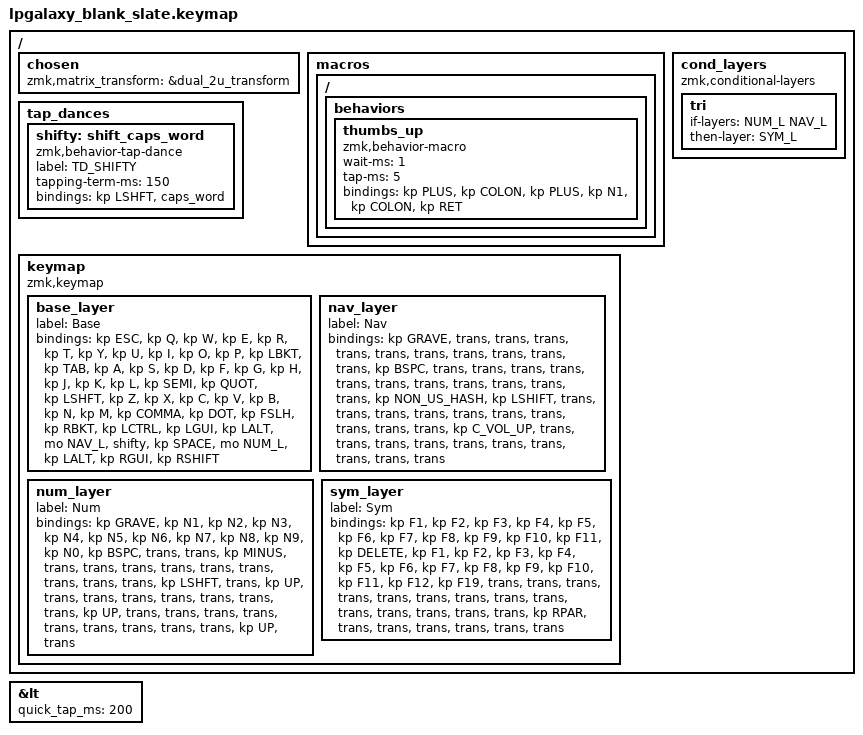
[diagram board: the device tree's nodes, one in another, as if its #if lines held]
/*
 * Copyright (c) 2022 Pete Johanson
 *
 * SPDX-License-Identifier: MIT
 */

#include <behaviors.dtsi>
#include <dt-bindings/zmk/keys.h>
#include <dt-bindings/zmk/bt.h>
#include <dt-bindings/zmk/outputs.h>

#define QWERTY_BASE 1

#define TBLE_MIT     1
// #define TBLE_MIT     1
// #define TBLE_DUAL_2U 1

#define NAV_L 1
#define NUM_L 2
#define SYM_L 3

// Using layer taps on thumbs, having quick tap as well helps w/ repeating space/backspace
&lt { quick_tap_ms = <200>; };

#define BT(n) BT_SEL n

/ {
    chosen {
       zmk,matrix_transform =
#ifdef TBLE_DUAL_2U
                       &dual_2u_transform;
#elif defined(TBLE_MIT)
                       &mit_transform;
#else
                       &ortho_transform;
#endif
    };

    macros {
      ZMK_MACRO(thumbs_up,
		wait-ms = <1>;
		tap-ms = <5>;
                bindings = <&kp PLUS &kp COLON &kp PLUS &kp N1 &kp COLON &kp RET>;
		)
    };
    
    tap_dances {
    	shifty: shift_caps_word {
		compatible = "zmk,behavior-tap-dance";
		label = "TD_SHIFTY";
		#binding-cells = <0>;
		tapping-term-ms = <150>;
		bindings = <&kp LSHFT>, <&caps_word>;
	};
    };

// Conditional layer only when we have less thumb keys
#ifdef TBLE_DUAL_2U
    cond_layers {
        compatible = "zmk,conditional-layers";
	tri {
	    if-layers = <NUM_L NAV_L>;
	    then-layer = <SYM_L>;
        };
    };
#endif

    keymap {
        compatible = "zmk,keymap";

        base_layer {
            label = "Base";
            bindings = <
#ifdef QWERTY_BASE
 &kp ESC    &kp Q      &kp W      &kp E       &kp R          &kp T          &kp Y            &kp U          &kp I       &kp O      &kp P         &kp LBKT
 &kp TAB    &kp A      &kp S      &kp D       &kp F          &kp G          &kp H            &kp J          &kp K       &kp L      &kp SEMI      &kp QUOT
 &kp LSHFT  &kp Z      &kp X      &kp C       &kp V          &kp B          &kp N            &kp M          &kp COMMA   &kp DOT    &kp FSLH      &kp RBKT
#else
 &kp ESC    &kp Q      &kp W      &kp F       &kp P          &kp B          &kp J            &kp L          &kp U       &kp Y      &kp QUOT      &kp BKSP
 &kp TAB    &kp A      &kp R      &kp S       &kp T          &kp G          &kp M            &kp N          &kp E       &kp I      &kp O         &kp QUOT
 &kp LSHFT  &kp Z      &kp X      &kp C       &kp D          &kp V          &kp K            &kp H          &kp COMMA   &kp DOT    &kp SEMI      &kp RET
#endif
#ifdef TBLE_DUAL_2U
 &kp LCTRL  &kp LGUI   &kp LALT   &mo NAV_L         &shifty                        &kp SPACE                &mo NUM_L   &kp LALT   &kp RGUI      &kp RSHIFT
#elif defined(TBLE_MIT)
 &kp LCTRL  &mo SYM_L   &kp LGUI  &kp LALT    &mo NAV_L          &kp SPACE                   &mo NUM_L      &kp RIGHT_ALT    &kp MINUS     &kp CAPSLOCK      &kp RETURN
#else
 &kp LCTRL  &mo SYM_L   &kp LGUI  &kp LALT    &mo NAV_L      &kp SPACE      &kp RET          &mo NUM_L      &kp LEFT    &kp UP     &kp DOWN      &kp RIGHT
#endif
            >;
        };

        nav_layer {
            label = "Nav";
            bindings = <
&kp GRAVE     &trans     &trans     &trans      &trans          &trans       &trans     &trans       &trans     &trans     &trans     &kp BSPC
&trans     &trans     &trans     &trans      &trans          &trans       &trans     &trans       &trans     &trans     &trans     &kp NON_US_HASH
&kp LSHIFT     &trans     &trans     &trans      &trans          &trans       &trans     &trans       &trans     &trans     &trans     &kp C_VOL_UP 
#ifdef TBLE_DUAL_2U
&trans  &trans        &trans     &trans              &trans                    &trans       &trans         &trans &trans &trans
#elif defined(TBLE_MIT)
&trans  &trans        &trans     &trans      &trans                &trans             &trans      &trans   &kp QMARK &kp C_PLAY_PAUSE &kp C_VOLUME_DOWN
#else
&trans  &trans        &trans     &trans      &trans          &trans       &trans    &trans  &trans         &trans &trans &trans
#endif
            >;
        };

        num_layer {
            label = "Num";
            bindings = <
&kp GRAVE     &kp N1   &kp N2      &kp N3  &kp N4    &kp N5      &kp N6       &kp N7     &kp N8      &kp N9       &kp N0     &kp BSPC
&trans     &trans   &kp MINUS   &trans  &trans    &trans   &trans    &trans     &trans      &trans       &trans     &trans
&kp LSHFT     &trans   &kp UP      &trans  &trans    &trans        &trans       &trans     &trans      &trans       &kp UP     &trans
#ifdef TBLE_DUAL_2U
&trans  &trans       &trans     &trans              &trans                 &trans            &trans         &trans &kp UP &trans
#elif defined(TBLE_MIT)
&trans  &kp LEFT       &kp DOWN     &kp RIGHT      &trans           &none            &trans        &trans     &kp LEFT &kp DOWN &kp RIGHT
#else
&trans  &trans       &trans     &kp N0      &trans    &none         &none     &kp ESC        &kp DEL      &kp LEFT &kp DOWN &kp RIGHT
#endif
            >;
        };

        sym_layer {
            label = "Sym";
            bindings = <
&kp F1    &kp F2   &kp F3   &kp F4    &kp F5     &kp F6     &kp F7     &kp F8    &kp F9       &kp F10       &kp F11     &kp DELETE
&kp F1    &kp F2   &kp F3   &kp F4    &kp F5     &kp F6     &kp F7     &kp F8    &kp F9       &kp F10       &kp F11     &kp F12
&kp F19     &trans  &trans   &trans      &trans     &trans     &trans     &trans    &trans       &trans       &trans     &trans
#ifdef TBLE_DUAL_2U
&trans &trans        &trans     &kp RPAR                &trans                    &trans       &trans         &trans &trans &trans
#elif defined(TBLE_MIT)
&bootloader &trans        &trans     &trans        &trans                &trans             &trans      &trans   &trans &trans &bt BT_CLR
#else
&trans &trans        &trans     &kp RPAR        &trans          &trans       &trans    &trans  &trans         &trans &trans &trans
#endif
            >;
        };


    };
};

